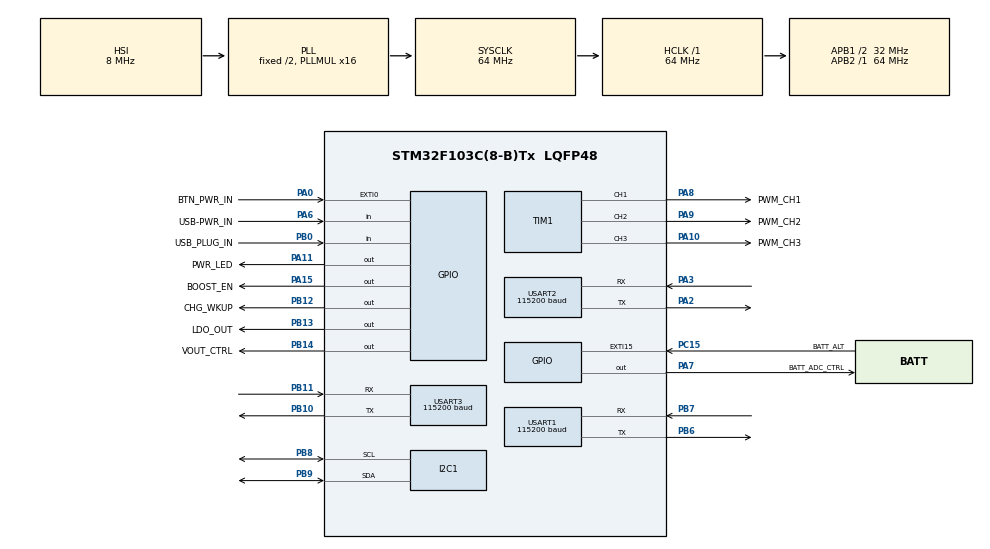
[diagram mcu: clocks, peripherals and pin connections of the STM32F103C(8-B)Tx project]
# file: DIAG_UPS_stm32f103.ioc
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Mcu.Family=STM32F1
Mcu.Name=STM32F103C(8-B)Tx
Mcu.Package=LQFP48
NVIC.PriorityGroup=NVIC_PRIORITYGROUP_4
PA0-WKUP.GPIO_Label=BTN_PWR_IN
PA0-WKUP.Signal=GPXTI0
PA10.GPIO_Label=PWM_CH3
PA10.Signal=S_TIM1_CH3
PA11.GPIO_Label=PWR_LED
PA11.PinState=GPIO_PIN_SET
PA11.Signal=GPIO_Output
PA13.Mode=Serial_Wire
PA13.Signal=SYS_JTMS-SWDIO
PA14.Mode=Serial_Wire
PA14.Signal=SYS_JTCK-SWCLK
PA15.GPIO_Label=BOOST_EN
PA15.Signal=GPIO_Output
PA2.Mode=Asynchronous
PA2.Signal=USART2_TX
PA3.Mode=Asynchronous
PA3.Signal=USART2_RX
PA6.GPIO_Label=USB-PWR_IN
PA6.Signal=GPIO_Input
PA7.GPIO_Label=BATT_ADC_CTRL
PA7.Signal=GPIO_Output
PA8.GPIO_Label=PWM_CH1
PA8.Signal=S_TIM1_CH1
PA9.GPIO_Label=PWM_CH2
PA9.Signal=S_TIM1_CH2
PB0.GPIO_Label=USB_PLUG_IN
PB0.Signal=GPIO_Input
PB10.Mode=Asynchronous
PB10.Signal=USART3_TX
PB11.Mode=Asynchronous
PB11.Signal=USART3_RX
PB12.GPIO_Label=CHG_WKUP
PB12.GPIO_ModeDefaultOutputPP=GPIO_MODE_OUTPUT_OD
PB12.GPIO_PuPd=GPIO_NOPULL
PB12.PinState=GPIO_PIN_SET
PB12.Signal=GPIO_Output
PB13.GPIO_Label=LDO_OUT
PB13.Signal=GPIO_Output
PB14.GPIO_Label=VOUT_CTRL
PB14.Signal=GPIO_Output
PB6.Mode=Asynchronous
PB6.Signal=USART1_TX
PB7.Mode=Asynchronous
PB7.Signal=USART1_RX
PB8.Mode=I2C
PB8.Signal=I2C1_SCL
PB9.Mode=I2C
PB9.Signal=I2C1_SDA
PC15-OSC32_OUT.GPIO_Label=BATT_ALT
PC15-OSC32_OUT.Signal=GPXTI15
ProjectManager.HeapSize=0x200
ProjectManager.StackSize=0x400
ProjectManager.TargetToolchain=MDK-ARM V5.27
RCC.ADCPresc=RCC_ADCPCLK2_DIV6
RCC.AHBFreq_Value=64000000
RCC.APB1CLKDivider=RCC_HCLK_DIV2
RCC.APB1Freq_Value=32000000
RCC.APB1TimFreq_Value=64000000
RCC.APB2Freq_Value=64000000
RCC.APB2TimFreq_Value=64000000
RCC.HCLKFreq_Value=64000000
RCC.PLLMUL=RCC_PLL_MUL16
RCC.SYSCLKFreq_VALUE=64000000
RCC.SYSCLKSource=RCC_SYSCLKSOURCE_PLLCLK
RCC.USBFreq_Value=64000000
SH.S_TIM1_CH1.0=TIM1_CH1,PWM Generation1 CH1
SH.S_TIM1_CH2.0=TIM1_CH2,PWM Generation2 CH2
SH.S_TIM1_CH3.0=TIM1_CH3,PWM Generation3 CH3
TIM1.Channel-PWM\ Generation1\ CH1=TIM_CHANNEL_1
TIM1.Channel-PWM\ Generation2\ CH2=TIM_CHANNEL_2
TIM1.Channel-PWM\ Generation3\ CH3=TIM_CHANNEL_3
USART1.BaudRate=115200
USART1.Parity=PARITY_NONE
USART1.StopBits=STOPBITS_1
USART1.VirtualMode=VM_ASYNC
USART1.WordLength=WORDLENGTH_8B
USART2.BaudRate=115200
USART2.Parity=PARITY_NONE
USART2.StopBits=STOPBITS_1
USART2.VirtualMode=VM_ASYNC
USART2.WordLength=WORDLENGTH_8B
USART3.BaudRate=115200
USART3.Parity=PARITY_NONE
USART3.StopBits=STOPBITS_1
USART3.VirtualMode=VM_ASYNC
USART3.WordLength=WORDLENGTH_8B
VP_TIM1_VS_ClockSourceINT.Mode=Internal
board=custom

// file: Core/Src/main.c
/* USER CODE BEGIN Header */
/**
  ******************************************************************************
  * @file           : main.c
  * @brief          : Main program body
  ******************************************************************************
  * @attention
  *
  * Copyright (c) 2026 STMicroelectronics.
  * All rights reserved.
  *
  * This software is licensed under terms that can be found in the LICENSE file
  * in the root directory of this software component.
  * If no LICENSE file comes with this software, it is provided AS-IS.
  *
  ******************************************************************************
  */
/* USER CODE END Header */
#include "main.h"

/* USER CODE BEGIN Includes */
#include "myapp.h"
#include "power_control.h"
#include "debug_log.h"
#include "rgb_led.h"
/* USER CODE END Includes */

I2C_HandleTypeDef hi2c1;

TIM_HandleTypeDef htim1;

UART_HandleTypeDef huart1;
UART_HandleTypeDef huart2;
UART_HandleTypeDef huart3;

void SystemClock_Config(void);
static void MX_GPIO_Init(void);
static void MX_I2C1_Init(void);
static void MX_TIM1_Init(void);
static void MX_USART1_UART_Init(void);
static void MX_USART2_UART_Init(void);
static void MX_USART3_UART_Init(void);

int main(void)
{

  /* MCU Configuration--------------------------------------------------------*/

  /* Reset of all peripherals, Initializes the Flash interface and the Systick. */
  HAL_Init();

  /* Configure the system clock */
  SystemClock_Config();

  /* Initialize all configured peripherals */
  MX_GPIO_Init();
  MX_I2C1_Init();
  MX_TIM1_Init();
  MX_USART1_UART_Init();
  MX_USART2_UART_Init();
  MX_USART3_UART_Init();
  /* USER CODE BEGIN 2 */
  App_Start(); /* never returns */

  /* USER CODE END 2 */

  /* Infinite loop */
  /* USER CODE BEGIN WHILE */
  while (1)
  {
    App_Start();
  }
  /* USER CODE END 3 */
}

void SystemClock_Config(void)
{
  RCC_OscInitTypeDef RCC_OscInitStruct = {0};
  RCC_ClkInitTypeDef RCC_ClkInitStruct = {0};

  /** Initializes the RCC Oscillators according to the specified parameters
  * in the RCC_OscInitTypeDef structure.
  */
  RCC_OscInitStruct.OscillatorType = RCC_OSCILLATORTYPE_HSI;
  RCC_OscInitStruct.HSIState = RCC_HSI_ON;
  RCC_OscInitStruct.HSICalibrationValue = RCC_HSICALIBRATION_DEFAULT;
  RCC_OscInitStruct.PLL.PLLState = RCC_PLL_ON;
  RCC_OscInitStruct.PLL.PLLSource = RCC_PLLSOURCE_HSI_DIV2;
  RCC_OscInitStruct.PLL.PLLMUL = RCC_PLL_MUL16;
  if (HAL_RCC_OscConfig(&RCC_OscInitStruct) != HAL_OK)
  {
    Error_Handler();
  }

  /** Initializes the CPU, AHB and APB buses clocks
  */
  RCC_ClkInitStruct.ClockType = RCC_CLOCKTYPE_HCLK|RCC_CLOCKTYPE_SYSCLK
                              |RCC_CLOCKTYPE_PCLK1|RCC_CLOCKTYPE_PCLK2;
  RCC_ClkInitStruct.SYSCLKSource = RCC_SYSCLKSOURCE_PLLCLK;
  RCC_ClkInitStruct.AHBCLKDivider = RCC_SYSCLK_DIV1;
  RCC_ClkInitStruct.APB1CLKDivider = RCC_HCLK_DIV2;
  RCC_ClkInitStruct.APB2CLKDivider = RCC_HCLK_DIV1;

  if (HAL_RCC_ClockConfig(&RCC_ClkInitStruct, FLASH_LATENCY_2) != HAL_OK)
  {
    Error_Handler();
  }
}

static void MX_I2C1_Init(void)
{

  hi2c1.Instance = I2C1;
  hi2c1.Init.ClockSpeed = 100000;
  hi2c1.Init.DutyCycle = I2C_DUTYCYCLE_2;
  hi2c1.Init.OwnAddress1 = 0;
  hi2c1.Init.AddressingMode = I2C_ADDRESSINGMODE_7BIT;
  hi2c1.Init.DualAddressMode = I2C_DUALADDRESS_DISABLE;
  hi2c1.Init.OwnAddress2 = 0;
  hi2c1.Init.GeneralCallMode = I2C_GENERALCALL_DISABLE;
  hi2c1.Init.NoStretchMode = I2C_NOSTRETCH_DISABLE;
  if (HAL_I2C_Init(&hi2c1) != HAL_OK)
  {
    Error_Handler();
  }

}

static void MX_TIM1_Init(void)
{

  TIM_ClockConfigTypeDef sClockSourceConfig = {0};
  TIM_MasterConfigTypeDef sMasterConfig = {0};
  TIM_OC_InitTypeDef sConfigOC = {0};
  TIM_BreakDeadTimeConfigTypeDef sBreakDeadTimeConfig = {0};

  htim1.Instance = TIM1;
  htim1.Init.Prescaler = 0;
  htim1.Init.CounterMode = TIM_COUNTERMODE_UP;
  htim1.Init.Period = 65535;
  htim1.Init.ClockDivision = TIM_CLOCKDIVISION_DIV1;
  htim1.Init.RepetitionCounter = 0;
  htim1.Init.AutoReloadPreload = TIM_AUTORELOAD_PRELOAD_DISABLE;
  if (HAL_TIM_Base_Init(&htim1) != HAL_OK)
  {
    Error_Handler();
  }
  sClockSourceConfig.ClockSource = TIM_CLOCKSOURCE_INTERNAL;
  if (HAL_TIM_ConfigClockSource(&htim1, &sClockSourceConfig) != HAL_OK)
  {
    Error_Handler();
  }
  if (HAL_TIM_PWM_Init(&htim1) != HAL_OK)
  {
    Error_Handler();
  }
  sMasterConfig.MasterOutputTrigger = TIM_TRGO_RESET;
  sMasterConfig.MasterSlaveMode = TIM_MASTERSLAVEMODE_DISABLE;
  if (HAL_TIMEx_MasterConfigSynchronization(&htim1, &sMasterConfig) != HAL_OK)
  {
    Error_Handler();
  }
  sConfigOC.OCMode = TIM_OCMODE_PWM1;
  sConfigOC.Pulse = 0;
  sConfigOC.OCPolarity = TIM_OCPOLARITY_HIGH;
  sConfigOC.OCNPolarity = TIM_OCNPOLARITY_HIGH;
  sConfigOC.OCFastMode = TIM_OCFAST_DISABLE;
  sConfigOC.OCIdleState = TIM_OCIDLESTATE_RESET;
  sConfigOC.OCNIdleState = TIM_OCNIDLESTATE_RESET;
  if (HAL_TIM_PWM_ConfigChannel(&htim1, &sConfigOC, TIM_CHANNEL_1) != HAL_OK)
  {
    Error_Handler();
  }
  if (HAL_TIM_PWM_ConfigChannel(&htim1, &sConfigOC, TIM_CHANNEL_2) != HAL_OK)
  {
    Error_Handler();
  }
  if (HAL_TIM_PWM_ConfigChannel(&htim1, &sConfigOC, TIM_CHANNEL_3) != HAL_OK)
  {
    Error_Handler();
  }
  sBreakDeadTimeConfig.OffStateRunMode = TIM_OSSR_DISABLE;
  sBreakDeadTimeConfig.OffStateIDLEMode = TIM_OSSI_DISABLE;
  sBreakDeadTimeConfig.LockLevel = TIM_LOCKLEVEL_OFF;
  sBreakDeadTimeConfig.DeadTime = 0;
  sBreakDeadTimeConfig.BreakState = TIM_BREAK_DISABLE;
  sBreakDeadTimeConfig.BreakPolarity = TIM_BREAKPOLARITY_HIGH;
  sBreakDeadTimeConfig.AutomaticOutput = TIM_AUTOMATICOUTPUT_DISABLE;
  if (HAL_TIMEx_ConfigBreakDeadTime(&htim1, &sBreakDeadTimeConfig) != HAL_OK)
  {
    Error_Handler();
  }
  HAL_TIM_MspPostInit(&htim1);

}

static void MX_USART1_UART_Init(void)
{

  huart1.Instance = USART1;
  huart1.Init.BaudRate = 115200;
  huart1.Init.WordLength = UART_WORDLENGTH_8B;
  huart1.Init.StopBits = UART_STOPBITS_1;
  huart1.Init.Parity = UART_PARITY_NONE;
  huart1.Init.Mode = UART_MODE_TX_RX;
  huart1.Init.HwFlowCtl = UART_HWCONTROL_NONE;
  huart1.Init.OverSampling = UART_OVERSAMPLING_16;
  if (HAL_UART_Init(&huart1) != HAL_OK)
  {
    Error_Handler();
  }

}

static void MX_USART2_UART_Init(void)
{

  huart2.Instance = USART2;
  huart2.Init.BaudRate = 115200;
  huart2.Init.WordLength = UART_WORDLENGTH_8B;
  huart2.Init.StopBits = UART_STOPBITS_1;
  huart2.Init.Parity = UART_PARITY_NONE;
  huart2.Init.Mode = UART_MODE_TX_RX;
  huart2.Init.HwFlowCtl = UART_HWCONTROL_NONE;
  huart2.Init.OverSampling = UART_OVERSAMPLING_16;
  if (HAL_UART_Init(&huart2) != HAL_OK)
  {
    Error_Handler();
  }

}

static void MX_USART3_UART_Init(void)
{

  huart3.Instance = USART3;
  huart3.Init.BaudRate = 115200;
  huart3.Init.WordLength = UART_WORDLENGTH_8B;
  huart3.Init.StopBits = UART_STOPBITS_1;
  huart3.Init.Parity = UART_PARITY_NONE;
  huart3.Init.Mode = UART_MODE_TX_RX;
  huart3.Init.HwFlowCtl = UART_HWCONTROL_NONE;
  huart3.Init.OverSampling = UART_OVERSAMPLING_16;
  if (HAL_UART_Init(&huart3) != HAL_OK)
  {
    Error_Handler();
  }

}

static void MX_GPIO_Init(void)
{
  GPIO_InitTypeDef GPIO_InitStruct = {0};

  /* GPIO Ports Clock Enable */
  __HAL_RCC_GPIOC_CLK_ENABLE();
  __HAL_RCC_GPIOA_CLK_ENABLE();
  __HAL_RCC_GPIOB_CLK_ENABLE();

  /*Configure GPIO pin Output Level */
  HAL_GPIO_WritePin(GPIOA, BATT_ADC_CTRL_Pin|PWR_LED_Pin|BOOST_EN_Pin, GPIO_PIN_RESET);

  /*Configure GPIO pin Output Level */
  HAL_GPIO_WritePin(CHG_WKUP_GPIO_Port, CHG_WKUP_Pin, GPIO_PIN_SET);

  /*Configure GPIO pin Output Level */
  HAL_GPIO_WritePin(GPIOB, LDO_OUT_Pin|VOUT_CTRL_Pin, GPIO_PIN_RESET);

  /*Configure GPIO pin : BATT_ALT_Pin */
  GPIO_InitStruct.Pin = BATT_ALT_Pin;
  GPIO_InitStruct.Mode = GPIO_MODE_IT_RISING;
  GPIO_InitStruct.Pull = GPIO_NOPULL;
  HAL_GPIO_Init(BATT_ALT_GPIO_Port, &GPIO_InitStruct);

  /*Configure GPIO pin : BTN_PWR_IN_Pin */
  GPIO_InitStruct.Pin = BTN_PWR_IN_Pin;
  GPIO_InitStruct.Mode = GPIO_MODE_IT_RISING;
  GPIO_InitStruct.Pull = GPIO_NOPULL;
  HAL_GPIO_Init(BTN_PWR_IN_GPIO_Port, &GPIO_InitStruct);

  /*Configure GPIO pin : USB_PWR_IN_Pin */
  GPIO_InitStruct.Pin = USB_PWR_IN_Pin;
  GPIO_InitStruct.Mode = GPIO_MODE_INPUT;
  GPIO_InitStruct.Pull = GPIO_NOPULL;
  HAL_GPIO_Init(USB_PWR_IN_GPIO_Port, &GPIO_InitStruct);

  /*Configure GPIO pins : BATT_ADC_CTRL_Pin PWR_LED_Pin BOOST_EN_Pin */
  GPIO_InitStruct.Pin = BATT_ADC_CTRL_Pin|PWR_LED_Pin|BOOST_EN_Pin;
  GPIO_InitStruct.Mode = GPIO_MODE_OUTPUT_PP;
  GPIO_InitStruct.Pull = GPIO_NOPULL;
  GPIO_InitStruct.Speed = GPIO_SPEED_FREQ_LOW;
  HAL_GPIO_Init(GPIOA, &GPIO_InitStruct);

  /*Configure GPIO pin : USB_PLUG_IN_Pin */
  GPIO_InitStruct.Pin = USB_PLUG_IN_Pin;
  GPIO_InitStruct.Mode = GPIO_MODE_INPUT;
  GPIO_InitStruct.Pull = GPIO_NOPULL;
  HAL_GPIO_Init(USB_PLUG_IN_GPIO_Port, &GPIO_InitStruct);

  /*Configure GPIO pin : CHG_WKUP_Pin */
  GPIO_InitStruct.Pin = CHG_WKUP_Pin;
  GPIO_InitStruct.Mode = GPIO_MODE_OUTPUT_OD;
  GPIO_InitStruct.Pull = GPIO_NOPULL;
  GPIO_InitStruct.Speed = GPIO_SPEED_FREQ_LOW;
  HAL_GPIO_Init(CHG_WKUP_GPIO_Port, &GPIO_InitStruct);

  /*Configure GPIO pins : LDO_OUT_Pin VOUT_CTRL_Pin */
  GPIO_InitStruct.Pin = LDO_OUT_Pin|VOUT_CTRL_Pin;
  GPIO_InitStruct.Mode = GPIO_MODE_OUTPUT_PP;
  GPIO_InitStruct.Pull = GPIO_NOPULL;
  GPIO_InitStruct.Speed = GPIO_SPEED_FREQ_LOW;
  HAL_GPIO_Init(GPIOB, &GPIO_InitStruct);

  /* USER CODE BEGIN MX_GPIO_Init_2 */
  /* PWR_LED is unused: keep it OFF (HIGH). The .ioc sets PinState=SET, so
     regenerated code does this itself; kept here until then. */
  HAL_GPIO_WritePin(PWR_LED_GPIO_Port, PWR_LED_Pin, GPIO_PIN_SET);

  /* BATT_ALT: MAX17048 ALRT is open-drain/active-low with no external
     pull-up on the board, so it needs an internal pull-up + falling-edge
     trigger -- CubeMX's default (NOPULL + IT_RISING) leaves the line
     floating while released and falsely raises the low-battery alert.
     Re-applied here because regeneration resets it. */
  GPIO_InitStruct.Pin = BATT_ALT_Pin;
  GPIO_InitStruct.Mode = GPIO_MODE_IT_FALLING;
  GPIO_InitStruct.Pull = GPIO_PULLUP;
  HAL_GPIO_Init(BATT_ALT_GPIO_Port, &GPIO_InitStruct);

  /* Not enabled by the .ioc yet: NVIC for the power button (PA0) and the
     fuel-gauge alert (PC15). */
  HAL_NVIC_SetPriority(EXTI0_IRQn, 3, 0);
  HAL_NVIC_EnableIRQ(EXTI0_IRQn);

  HAL_NVIC_SetPriority(EXTI15_10_IRQn, 3, 0);
  HAL_NVIC_EnableIRQ(EXTI15_10_IRQn);
  /* USER CODE END MX_GPIO_Init_2 */
}

void Error_Handler(void)
{
  __disable_irq();
  while (1)
  {
  }
}
